# STM32G483xx register map
File version: 1.6
CPU: CM4 r0p1, little endian, MPU, FPU, 4 interrupt priority bits
Registers are 32-bit, read-write, reset 0x0 unless marked. A register's access mark holds for its fields unless they carry their own. Offsets are from the block's base; [hi:lo] are bit positions; {n}, {i} and the like mark numbered series; 'fields as' and 'values as' point back to an identical list.

## VREFBUF — Voltage reference buffer
Base 0x40010030
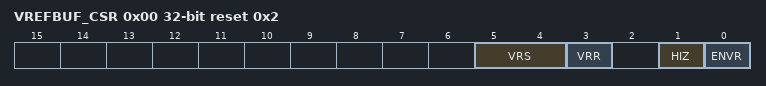
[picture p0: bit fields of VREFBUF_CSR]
0x00 VREFBUF_CSR access per field reset 0x2 — VREF_BUF Control and Status Register
  [5:4] VRS rw — Voltage reference scale
  [3] VRR ro — Voltage reference buffer ready
  [1] HIZ rw — High impedence mode for the VREF_BUF
  [0] ENVR rw — Enable Voltage Reference
0x04 VREFBUF_CCR — VREF_BUF Calibration Control Register
  [5:0] TRIM — Trimming code

## COMP — Comparator control and status register
Base 0x40010200
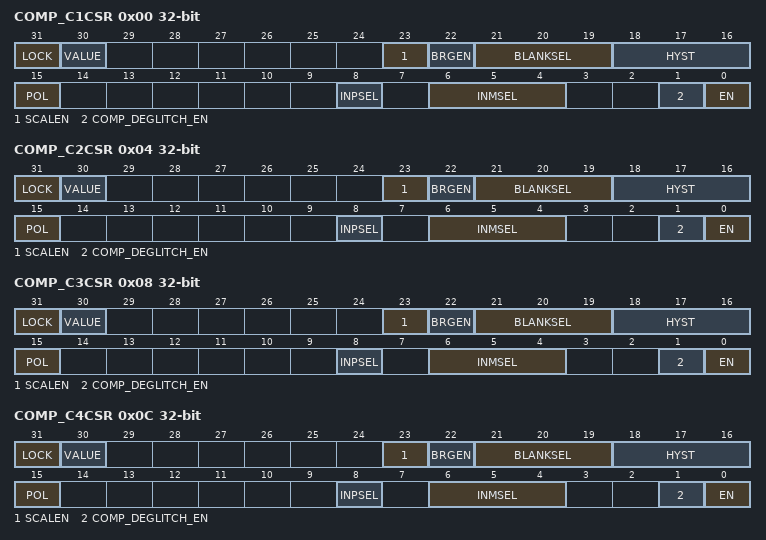
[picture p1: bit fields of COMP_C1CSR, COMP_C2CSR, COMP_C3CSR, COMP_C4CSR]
0x00 COMP_C1CSR access per field — Comparator control/status register
  [31] LOCK rw, [30] VALUE ro, [23] SCALEN rw, [22] BRGEN rw, [21:19] BLANKSEL rw, [18:16] HYST rw, [15] POL rw, [8] INPSEL rw, [6:4] INMSEL rw, [1] COMP_DEGLITCH_EN rw, [0] EN rw
0x04 COMP_C2CSR access per field — Comparator control/status register
  fields as COMP_C1CSR
0x08 COMP_C3CSR access per field — Comparator control/status register
  fields as COMP_C1CSR
0x0C COMP_C4CSR access per field — Comparator control/status register
  fields as COMP_C1CSR
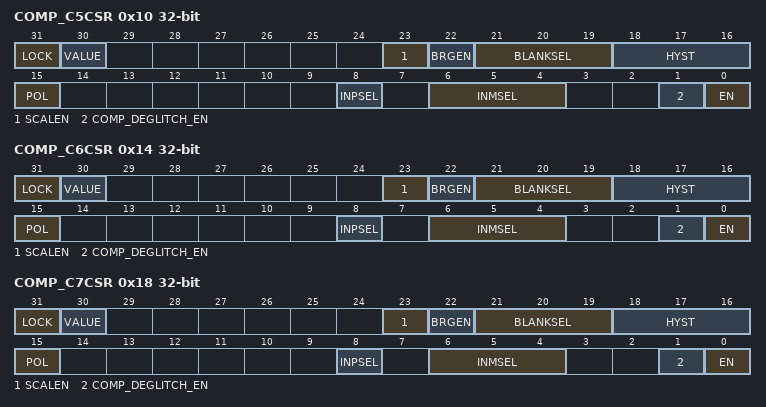
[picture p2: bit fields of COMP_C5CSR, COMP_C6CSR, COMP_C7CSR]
0x10 COMP_C5CSR access per field — Comparator control/status register
  fields as COMP_C1CSR
0x14 COMP_C6CSR access per field — Comparator control/status register
  fields as COMP_C1CSR
0x18 COMP_C7CSR access per field — Comparator control/status register
  fields as COMP_C1CSR

## OPAMP — Operational amplifiers
Base 0x40010300
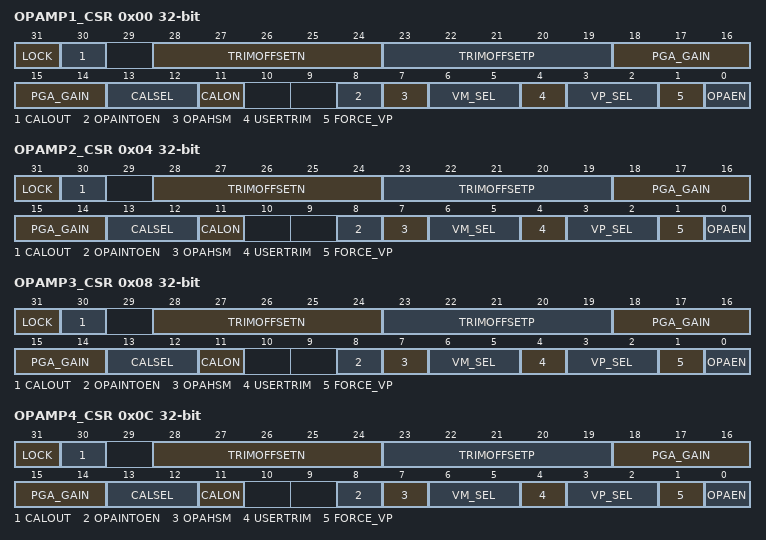
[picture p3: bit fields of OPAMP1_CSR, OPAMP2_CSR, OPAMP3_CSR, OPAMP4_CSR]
0x00 OPAMP1_CSR — OPAMP1 control/status register
  [31] LOCK
  [30] CALOUT
  [28:24] TRIMOFFSETN
  [23:19] TRIMOFFSETP
  [18:14] PGA_GAIN
  [13:12] CALSEL
  [11] CALON
  [8] OPAINTOEN
  [7] OPAHSM
  [6:5] VM_SEL
  [4] USERTRIM
  [3:2] VP_SEL
  [1] FORCE_VP
  [0] OPAEN — Operational amplifier Enable
0x04 OPAMP2_CSR — OPAMP2 control/status register
  fields as OPAMP1_CSR
0x08 OPAMP3_CSR — OPAMP3 control/status register
  fields as OPAMP1_CSR
0x0C OPAMP4_CSR — OPAMP4 control/status register
  fields as OPAMP1_CSR
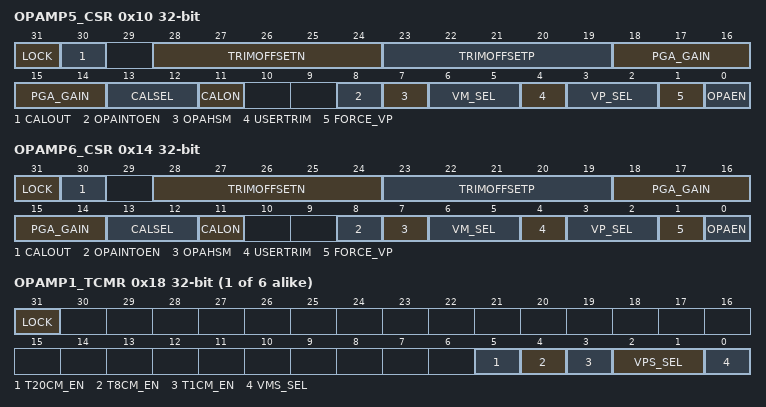
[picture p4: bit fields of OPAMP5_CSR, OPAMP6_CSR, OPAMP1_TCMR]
0x10 OPAMP5_CSR — OPAMP5 control/status register
  fields as OPAMP1_CSR
0x14 OPAMP6_CSR — OPAMP6 control/status register
  fields as OPAMP1_CSR
{0x14+4i} OPAMP{i}_TCMR (i=1..6) — OPAMP{i} control/status register
  [31] LOCK, [5] T20CM_EN, [4] T8CM_EN, [3] T1CM_EN, [2:1] VPS_SEL, [0] VMS_SEL

## QUADSPI — QuadSPI interface
Base 0xA0001000
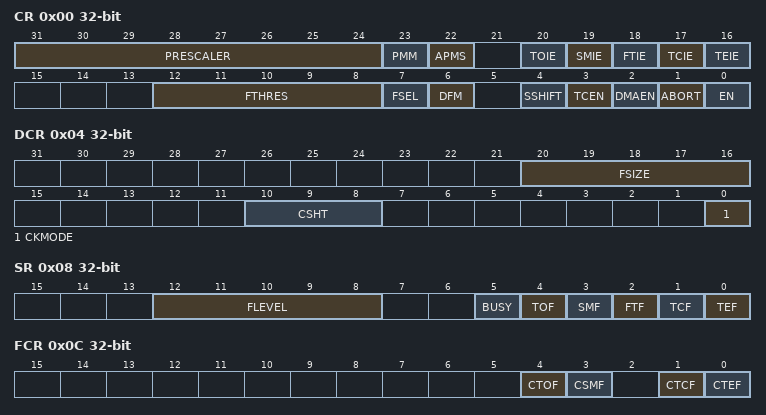
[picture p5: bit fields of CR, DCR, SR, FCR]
0x00 CR — control register
  [31:24] PRESCALER — Clock prescaler
  [23] PMM — Polling match mode
  [22] APMS — Automatic poll mode stop
  [20] TOIE — TimeOut interrupt enable
  [19] SMIE — Status match interrupt enable
  [18] FTIE — FIFO threshold interrupt enable
  [17] TCIE — Transfer complete interrupt enable
  [16] TEIE — Transfer error interrupt enable
  [12:8] FTHRES — IFO threshold level
  [7] FSEL
  [6] DFM
  [4] SSHIFT — Sample shift
  [3] TCEN — Timeout counter enable
  [2] DMAEN — DMA enable
  [1] ABORT — Abort request
  [0] EN — Enable
0x04 DCR — device configuration register
  [20:16] FSIZE — FLASH memory size
  [10:8] CSHT — Chip select high time
  [0] CKMODE — Mode 0 / mode 3
0x08 SR ro — status register
  [12:8] FLEVEL — FIFO level
  [5] BUSY
  [4] TOF — Timeout flag
  [3] SMF — Status match flag
  [2] FTF — FIFO threshold flag
  [1] TCF — Transfer complete flag
  [0] TEF — Transfer error flag
0x0C FCR — flag clear register
  [4] CTOF — Clear timeout flag
  [3] CSMF — Clear status match flag
  [1] CTCF — Clear transfer complete flag
  [0] CTEF — Clear transfer error flag
0x10 DLR — data length register
  [31:0] DL — Data length
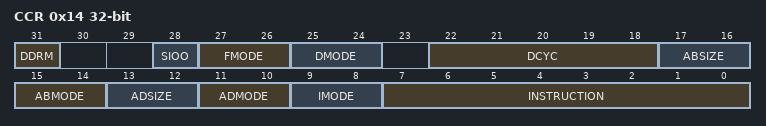
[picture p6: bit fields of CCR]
0x14 CCR — communication configuration register
  [31] DDRM — Double data rate mode
  [28] SIOO — Send instruction only once mode
  [27:26] FMODE — Functional mode
  [25:24] DMODE — Data mode
  [22:18] DCYC — Number of dummy cycles
  [17:16] ABSIZE — Alternate bytes size
  [15:14] ABMODE — Alternate bytes mode
  [13:12] ADSIZE — Address size
  [11:10] ADMODE — Address mode
  [9:8] IMODE — Instruction mode
  [7:0] INSTRUCTION
0x18 AR — address register
  [31:0] ADDRESS
0x1C ABR
  [31:0] ALTERNATE
0x20 DR — data register
  [31:0] DATA
0x24 PSMKR — polling status mask register
  [31:0] MASK — Status mask
0x28 PSMAR — polling status match register
  [31:0] MATCH — Status match
0x2C PIR — polling interval register
  [15:0] INTERVAL — Polling interval
0x30 LPTR — low-power timeout register
  [15:0] TIMEOUT — Timeout period
